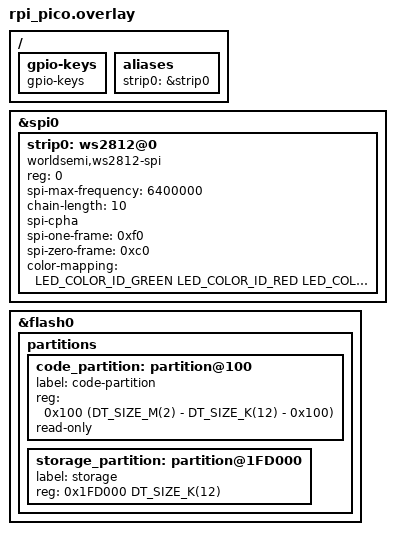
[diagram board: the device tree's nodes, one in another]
#include <zephyr/dt-bindings/led/led.h>

&spi0 {
    strip0: ws2812@0 {
        compatible = "worldsemi,ws2812-spi";

        /* SPI */
        reg = <0>; /* ignored, but necessary for SPI bindings */
        spi-max-frequency = <6400000>;

        /* WS2812 */
        chain-length = <10>;
        /* arbitrary; change at will */
        /* If changed, storage partition size has to be adjusted. */

        spi-cpha;
        spi-one-frame = <0xf0>; /* 11110000: 625 ns high and 625 ns low */
        spi-zero-frame = <0xc0>; /* 11000000: 312.5 ns high and 937.5 ns low */
        color-mapping = <LED_COLOR_ID_GREEN LED_COLOR_ID_RED LED_COLOR_ID_BLUE>;
    };
};

&flash0 {
    partitions {
        /* Remove 10 KiB to make space for storage partition */
        code_partition: partition@100 {
			label = "code-partition";
            // Remove 0x100 (256 bytes) from bootloader and 0x1000 (10 KiB) from storage_partition
			reg = <0x100 (DT_SIZE_M(2) - DT_SIZE_K(12) - 0x100)>;
			read-only;
		};

        /* Storage partition, for storing LED data (10 KiB) */
        storage_partition: partition@1FD000 {
            label = "storage";
            reg = <0x1FD000 DT_SIZE_K(12)>;
        };
    };    
};

/ {
    gpio-keys {
        compatible = "gpio-keys";
    };

    aliases {
        strip0 = &strip0;
    };
};

